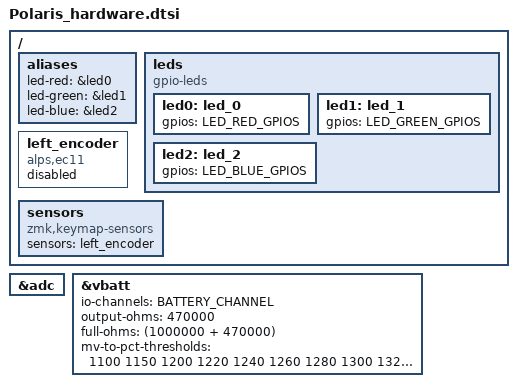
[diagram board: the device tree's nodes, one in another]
/ {
   aliases {
      led-red = &led0;
      led-green = &led1;
      led-blue = &led2;
   };

   leds {
      compatible = "gpio-leds";
      status = "okay";
      led0: led_0 {
        gpios = LED_RED_GPIOS;  // red LED, connected to P0.26
      };
      led1: led_1 {
        gpios = LED_GREEN_GPIOS;  // green LED, connected to P0.30
      };
      led2: led_2 {
        gpios = LED_BLUE_GPIOS;  // blue LED, connected to P0.06
      };
   };

   // Encoders
   left_encoder: left_encoder {
      compatible = "alps,ec11";
      status = "disabled";
   };

   sensors: sensors {
      compatible = "zmk,keymap-sensors";
      sensors = <&left_encoder>;
   };

};

&adc {
   status = "okay";
};

/*
 * Reuse the battery node supplied by xiao_ble//zmk, but preserve Polaris's
 * A0 1 MOhm / 470 kOhm divider and Ni-MH voltage curve. The carrier board
 * does not use the XIAO battery-enable GPIO.
 */
&vbatt {
   io-channels = BATTERY_CHANNEL;
   /delete-property/ power-gpios;
   output-ohms = <470000>;
   full-ohms = <(1000000 + 470000)>;
   mv-to-pct-thresholds = <1100 1150 1200 1220 1240 1260 1280 1300 1320 1350 1400>;
};
